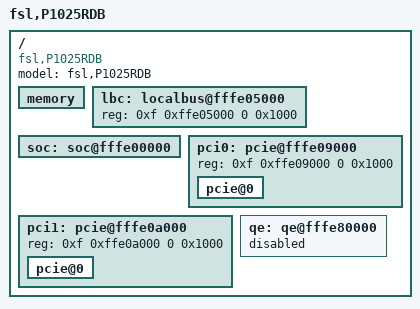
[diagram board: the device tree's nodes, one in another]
/include/ "p1021si-pre.dtsi"
/ {
	model = "fsl,P1025RDB";
	compatible = "fsl,P1025RDB";
	memory {
		device_type = "memory";
	};
	lbc: localbus@fffe05000 {
		reg = <0xf 0xffe05000 0 0x1000>;
		ranges = <0x0 0x0 0xf 0xef000000 0x01000000
			  0x1 0x0 0xf 0xff800000 0x00040000>;
	};
	soc: soc@fffe00000 {
		ranges = <0x0 0xf 0xffe00000 0x100000>;
	};
	pci0: pcie@fffe09000 {
		reg = <0xf 0xffe09000 0 0x1000>;
		ranges = <0x2000000 0x0 0xe0000000 0xe 0x20000000 0x0 0x20000000
			  0x1000000 0x0 0x00000000 0xf 0xffc10000 0x0 0x10000>;
		pcie@0 {
			ranges = <0x2000000 0x0 0xe0000000
				  0x2000000 0x0 0xe0000000
				  0x0 0x20000000
				  0x1000000 0x0 0x0
				  0x1000000 0x0 0x0
				  0x0 0x100000>;
		};
	};
	pci1: pcie@fffe0a000 {
		reg = <0xf 0xffe0a000 0 0x1000>;
		ranges = <0x2000000 0x0 0xe0000000 0xc 0x00000000 0x0 0x20000000
			  0x1000000 0x0 0x00000000 0xf 0xffc00000 0x0 0x10000>;
		pcie@0 {
			ranges = <0x2000000 0x0 0xe0000000
				  0x2000000 0x0 0xe0000000
				  0x0 0x20000000
				  0x1000000 0x0 0x0
				  0x1000000 0x0 0x0
				  0x0 0x100000>;
		};
	};
	qe: qe@fffe80000 {
		status = "disabled";  
	};
};
/include/ "p1025rdb.dtsi"
/include/ "p1021si-post.dtsi"
